VERSION ""

NS_ :

BS_:

BU_: ECU

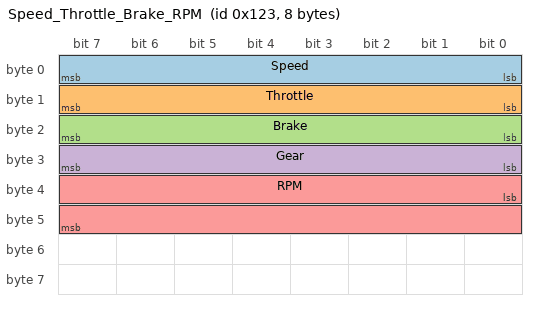
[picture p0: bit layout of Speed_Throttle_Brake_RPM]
BO_ 291 Speed_Throttle_Brake_RPM: 8 ECU
 SG_ Speed : 0|8@1+ (1,0) [0|255] "km/h"  Vector__XXX
 SG_ Throttle : 8|8@1+ (1,0) [0|100] "%"  Vector__XXX
 SG_ Brake : 16|8@1+ (1,0) [0|100] "%"  Vector__XXX
 SG_ Gear : 24|8@1+ (1,0) [0|15] ""  Vector__XXX
 SG_ RPM : 32|16@1+ (1,0) [0|65535] "rpm"  Vector__XXX
